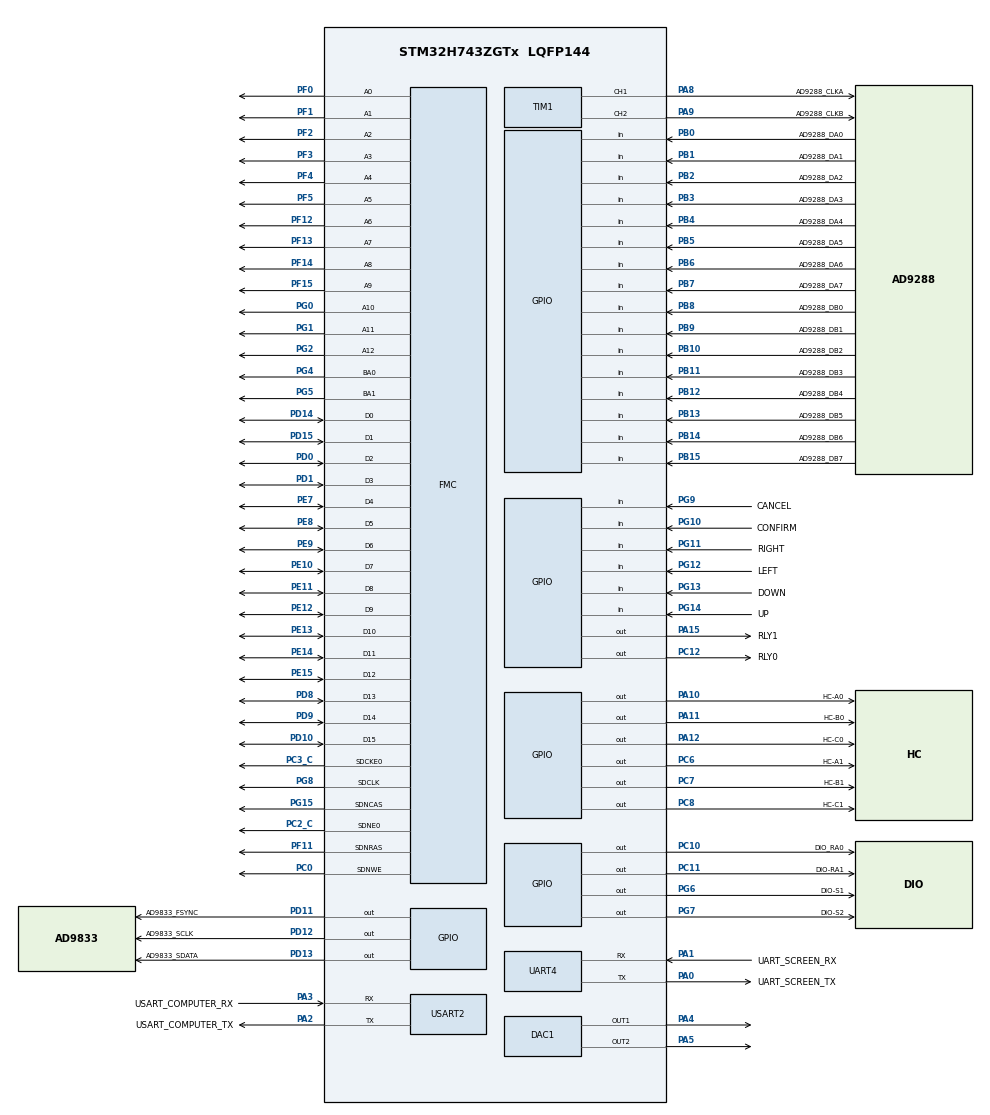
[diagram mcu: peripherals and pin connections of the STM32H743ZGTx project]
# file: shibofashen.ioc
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DAC1.DAC_Channel-DAC_OUT1=DAC_CHANNEL_1
DAC1.DAC_Channel-DAC_OUT2=DAC_CHANNEL_2
Dma.Request0=TIM1_CH1
Dma.Request1=TIM2_CH1
Dma.Request2=TIM2_CH2
Dma.Request3=TIM2_CH3
Dma.Request4=TIM2_CH4
Dma.Request5=UART4_TX
Dma.TIM1_CH1.0.Direction=DMA_PERIPH_TO_MEMORY
Dma.TIM1_CH1.0.EventEnable=DISABLE
Dma.TIM1_CH1.0.FIFOMode=DMA_FIFOMODE_DISABLE
Dma.TIM1_CH1.0.Instance=DMA1_Stream0
Dma.TIM1_CH1.0.MemDataAlignment=DMA_MDATAALIGN_HALFWORD
Dma.TIM1_CH1.0.MemInc=DMA_MINC_ENABLE
Dma.TIM1_CH1.0.Mode=DMA_NORMAL
Dma.TIM1_CH1.0.PeriphDataAlignment=DMA_PDATAALIGN_HALFWORD
Dma.TIM1_CH1.0.PeriphInc=DMA_PINC_DISABLE
Dma.TIM1_CH1.0.Polarity=HAL_DMAMUX_REQ_GEN_RISING
Dma.TIM1_CH1.0.Priority=DMA_PRIORITY_LOW
Dma.TIM1_CH1.0.RequestNumber=1
Dma.TIM1_CH1.0.SignalID=NONE
Dma.TIM1_CH1.0.SyncEnable=DISABLE
Dma.TIM1_CH1.0.SyncPolarity=HAL_DMAMUX_SYNC_NO_EVENT
Dma.TIM1_CH1.0.SyncRequestNumber=1
Dma.TIM1_CH1.0.SyncSignalID=NONE
Dma.TIM2_CH1.1.Direction=DMA_PERIPH_TO_MEMORY
Dma.TIM2_CH1.1.EventEnable=DISABLE
Dma.TIM2_CH1.1.FIFOMode=DMA_FIFOMODE_DISABLE
Dma.TIM2_CH1.1.Instance=DMA1_Stream1
Dma.TIM2_CH1.1.MemDataAlignment=DMA_MDATAALIGN_WORD
Dma.TIM2_CH1.1.MemInc=DMA_MINC_ENABLE
Dma.TIM2_CH1.1.Mode=DMA_NORMAL
Dma.TIM2_CH1.1.PeriphDataAlignment=DMA_PDATAALIGN_WORD
Dma.TIM2_CH1.1.PeriphInc=DMA_PINC_DISABLE
Dma.TIM2_CH1.1.Polarity=HAL_DMAMUX_REQ_GEN_RISING
Dma.TIM2_CH1.1.Priority=DMA_PRIORITY_LOW
Dma.TIM2_CH1.1.RequestNumber=1
Dma.TIM2_CH1.1.SignalID=NONE
Dma.TIM2_CH1.1.SyncEnable=DISABLE
Dma.TIM2_CH1.1.SyncPolarity=HAL_DMAMUX_SYNC_NO_EVENT
Dma.TIM2_CH1.1.SyncRequestNumber=1
Dma.TIM2_CH1.1.SyncSignalID=NONE
Dma.TIM2_CH2.2.Direction=DMA_PERIPH_TO_MEMORY
Dma.TIM2_CH2.2.EventEnable=DISABLE
Dma.TIM2_CH2.2.FIFOMode=DMA_FIFOMODE_DISABLE
Dma.TIM2_CH2.2.Instance=DMA1_Stream2
Dma.TIM2_CH2.2.MemDataAlignment=DMA_MDATAALIGN_WORD
Dma.TIM2_CH2.2.MemInc=DMA_MINC_ENABLE
Dma.TIM2_CH2.2.Mode=DMA_NORMAL
Dma.TIM2_CH2.2.PeriphDataAlignment=DMA_PDATAALIGN_WORD
Dma.TIM2_CH2.2.PeriphInc=DMA_PINC_DISABLE
Dma.TIM2_CH2.2.Polarity=HAL_DMAMUX_REQ_GEN_RISING
Dma.TIM2_CH2.2.Priority=DMA_PRIORITY_LOW
Dma.TIM2_CH2.2.RequestNumber=1
Dma.TIM2_CH2.2.SignalID=NONE
Dma.TIM2_CH2.2.SyncEnable=DISABLE
Dma.TIM2_CH2.2.SyncPolarity=HAL_DMAMUX_SYNC_NO_EVENT
Dma.TIM2_CH2.2.SyncRequestNumber=1
Dma.TIM2_CH2.2.SyncSignalID=NONE
Dma.TIM2_CH3.3.Direction=DMA_PERIPH_TO_MEMORY
Dma.TIM2_CH3.3.EventEnable=DISABLE
Dma.TIM2_CH3.3.FIFOMode=DMA_FIFOMODE_DISABLE
Dma.TIM2_CH3.3.Instance=DMA1_Stream3
Dma.TIM2_CH3.3.MemDataAlignment=DMA_MDATAALIGN_WORD
Dma.TIM2_CH3.3.MemInc=DMA_MINC_ENABLE
Dma.TIM2_CH3.3.Mode=DMA_NORMAL
Dma.TIM2_CH3.3.PeriphDataAlignment=DMA_PDATAALIGN_WORD
Dma.TIM2_CH3.3.PeriphInc=DMA_PINC_DISABLE
Dma.TIM2_CH3.3.Polarity=HAL_DMAMUX_REQ_GEN_RISING
Dma.TIM2_CH3.3.Priority=DMA_PRIORITY_LOW
Dma.TIM2_CH3.3.RequestNumber=1
Dma.TIM2_CH3.3.SignalID=NONE
Dma.TIM2_CH3.3.SyncEnable=DISABLE
Dma.TIM2_CH3.3.SyncPolarity=HAL_DMAMUX_SYNC_NO_EVENT
Dma.TIM2_CH3.3.SyncRequestNumber=1
Dma.TIM2_CH3.3.SyncSignalID=NONE
Dma.TIM2_CH4.4.Direction=DMA_PERIPH_TO_MEMORY
Dma.TIM2_CH4.4.EventEnable=DISABLE
Dma.TIM2_CH4.4.FIFOMode=DMA_FIFOMODE_ENABLE
Dma.TIM2_CH4.4.FIFOThreshold=DMA_FIFO_THRESHOLD_FULL
Dma.TIM2_CH4.4.Instance=DMA1_Stream4
Dma.TIM2_CH4.4.MemBurst=DMA_MBURST_SINGLE
Dma.TIM2_CH4.4.MemDataAlignment=DMA_MDATAALIGN_HALFWORD
Dma.TIM2_CH4.4.MemInc=DMA_MINC_ENABLE
Dma.TIM2_CH4.4.Mode=DMA_NORMAL
Dma.TIM2_CH4.4.PeriphBurst=DMA_PBURST_SINGLE
Dma.TIM2_CH4.4.PeriphDataAlignment=DMA_PDATAALIGN_HALFWORD
Dma.TIM2_CH4.4.PeriphInc=DMA_PINC_DISABLE
Dma.TIM2_CH4.4.Polarity=HAL_DMAMUX_REQ_GEN_RISING
Dma.TIM2_CH4.4.Priority=DMA_PRIORITY_LOW
Dma.TIM2_CH4.4.RequestNumber=1
Dma.TIM2_CH4.4.SignalID=NONE
Dma.TIM2_CH4.4.SyncEnable=DISABLE
Dma.TIM2_CH4.4.SyncPolarity=HAL_DMAMUX_SYNC_NO_EVENT
Dma.TIM2_CH4.4.SyncRequestNumber=1
Dma.TIM2_CH4.4.SyncSignalID=NONE
Dma.UART4_TX.5.Direction=DMA_MEMORY_TO_PERIPH
Dma.UART4_TX.5.EventEnable=DISABLE
Dma.UART4_TX.5.FIFOMode=DMA_FIFOMODE_DISABLE
Dma.UART4_TX.5.Instance=DMA1_Stream5
Dma.UART4_TX.5.MemDataAlignment=DMA_MDATAALIGN_BYTE
Dma.UART4_TX.5.MemInc=DMA_MINC_ENABLE
Dma.UART4_TX.5.Mode=DMA_NORMAL
Dma.UART4_TX.5.PeriphDataAlignment=DMA_PDATAALIGN_BYTE
Dma.UART4_TX.5.PeriphInc=DMA_PINC_DISABLE
Dma.UART4_TX.5.Polarity=HAL_DMAMUX_REQ_GEN_RISING
Dma.UART4_TX.5.Priority=DMA_PRIORITY_LOW
Dma.UART4_TX.5.RequestNumber=1
Dma.UART4_TX.5.SignalID=NONE
Dma.UART4_TX.5.SyncEnable=DISABLE
Dma.UART4_TX.5.SyncPolarity=HAL_DMAMUX_SYNC_NO_EVENT
Dma.UART4_TX.5.SyncRequestNumber=1
Dma.UART4_TX.5.SyncSignalID=NONE
FMC.ColumnBitsNumber1=FMC_SDRAM_COLUMN_BITS_NUM_9
FMC.ReadPipeDelay1=FMC_SDRAM_RPIPE_DELAY_1
FMC.ReadPipeDelay2=FMC_SDRAM_RPIPE_DELAY_1
FMC.SDClockPeriod1=FMC_SDRAM_CLOCK_PERIOD_2
FMC.SDClockPeriod2=FMC_SDRAM_CLOCK_PERIOD_2
Mcu.Family=STM32H7
Mcu.Name=STM32H743ZGTx
Mcu.Package=LQFP144
NVIC.DMA1_Stream0_IRQn=true\:0\:0\:false\:false\:true\:false\:true\:true
NVIC.DMA1_Stream1_IRQn=true\:0\:0\:false\:false\:true\:false\:true\:true
NVIC.DMA1_Stream2_IRQn=true\:0\:0\:false\:false\:true\:false\:true\:true
NVIC.DMA1_Stream3_IRQn=true\:0\:0\:false\:false\:true\:false\:true\:true
NVIC.DMA1_Stream4_IRQn=true\:0\:0\:false\:false\:true\:false\:true\:true
NVIC.DMA1_Stream5_IRQn=true\:0\:0\:false\:false\:true\:false\:true\:true
NVIC.PriorityGroup=NVIC_PRIORITYGROUP_4
NVIC.TIM2_IRQn=true\:0\:0\:false\:false\:true\:true\:true\:true
NVIC.TIM3_IRQn=true\:0\:0\:false\:false\:true\:true\:true\:true
NVIC.TIM4_IRQn=true\:0\:0\:false\:false\:true\:true\:true\:true
NVIC.TIM5_IRQn=true\:0\:0\:false\:false\:true\:true\:true\:true
PA0.GPIO_Label=UART_SCREEN_TX
PA0.Mode=Asynchronous
PA0.Signal=UART4_TX
PA1.GPIO_Label=UART_SCREEN_RX
PA1.Mode=Asynchronous
PA1.Signal=UART4_RX
PA10.GPIO_Label=HC-A0
PA10.Signal=GPIO_Output
PA11.GPIO_Label=HC-B0
PA11.Signal=GPIO_Output
PA12.GPIO_Label=HC-C0
PA12.Signal=GPIO_Output
PA13\ (JTMS/SWDIO).Mode=Serial_Wire
PA13\ (JTMS/SWDIO).Signal=DEBUG_JTMS-SWDIO
PA14\ (JTCK/SWCLK).Mode=Serial_Wire
PA14\ (JTCK/SWCLK).Signal=DEBUG_JTCK-SWCLK
PA15\ (JTDI).GPIO_Label=RLY1
PA15\ (JTDI).Signal=GPIO_Output
PA2.GPIO_Label=USART_COMPUTER_TX
PA2.Mode=Asynchronous
PA2.Signal=USART2_TX
PA3.GPIO_Label=USART_COMPUTER_RX
PA3.Mode=Asynchronous
PA3.Signal=USART2_RX
PA4.Signal=COMP_DAC11_group
PA5.Signal=COMP_DAC12_group
PA8.GPIO_Label=AD9288_CLKA
PA8.Signal=S_TIM1_CH1
PA9.GPIO_Label=AD9288_CLKB
PA9.Signal=S_TIM1_CH2
PB0.GPIO_Label=AD9288_DA0
PB0.Signal=GPIO_Input
PB1.GPIO_Label=AD9288_DA1
PB1.Signal=GPIO_Input
PB10.GPIO_Label=AD9288_DB2
PB10.Signal=GPIO_Input
PB11.GPIO_Label=AD9288_DB3
PB11.Signal=GPIO_Input
PB12.GPIO_Label=AD9288_DB4
PB12.Signal=GPIO_Input
PB13.GPIO_Label=AD9288_DB5
PB13.Signal=GPIO_Input
PB14.GPIO_Label=AD9288_DB6
PB14.Signal=GPIO_Input
PB15.GPIO_Label=AD9288_DB7
PB15.Signal=GPIO_Input
PB2.GPIO_Label=AD9288_DA2
PB2.Signal=GPIO_Input
PB3\ (JTDO/TRACESWO).GPIO_Label=AD9288_DA3
PB3\ (JTDO/TRACESWO).Signal=GPIO_Input
PB4\ (NJTRST).GPIO_Label=AD9288_DA4
PB4\ (NJTRST).Signal=GPIO_Input
PB5.GPIO_Label=AD9288_DA5
PB5.Signal=GPIO_Input
PB6.GPIO_Label=AD9288_DA6
PB6.Signal=GPIO_Input
PB7.GPIO_Label=AD9288_DA7
PB7.Signal=GPIO_Input
PB8.GPIO_Label=AD9288_DB0
PB8.Signal=GPIO_Input
PB9.GPIO_Label=AD9288_DB1
PB9.Signal=GPIO_Input
PC0.Signal=FMC_SDNWE
PC10.GPIO_Label=DIO_RA0
PC10.Signal=GPIO_Output
PC11.GPIO_Label=DIO-RA1
PC11.Signal=GPIO_Output
PC12.GPIO_Label=RLY0
PC12.Signal=GPIO_Output
PC2_C.Mode=SdramChipSelect1_1
PC2_C.Signal=FMC_SDNE0
PC3_C.Mode=SdramChipSelect1_1
PC3_C.Signal=FMC_SDCKE0
PC6.GPIO_Label=HC-A1
PC6.Signal=GPIO_Output
PC7.GPIO_Label=HC-B1
PC7.Signal=GPIO_Output
PC8.GPIO_Label=HC-C1
PC8.Signal=GPIO_Output
PD0.Signal=FMC_D2_DA2
PD1.Signal=FMC_D3_DA3
PD10.Signal=FMC_D15_DA15
PD11.GPIO_Label=AD9833_FSYNC
PD11.Signal=GPIO_Output
PD12.GPIO_Label=AD9833_SCLK
PD12.Signal=GPIO_Output
PD13.GPIO_Label=AD9833_SDATA
PD13.Signal=GPIO_Output
PD14.Signal=FMC_D0_DA0
PD15.Signal=FMC_D1_DA1
PD8.Signal=FMC_D13_DA13
PD9.Signal=FMC_D14_DA14
PE10.Signal=FMC_D7_DA7
PE11.Signal=FMC_D8_DA8
PE12.Signal=FMC_D9_DA9
PE13.Signal=FMC_D10_DA10
PE14.Signal=FMC_D11_DA11
PE15.Signal=FMC_D12_DA12
PE7.Signal=FMC_D4_DA4
PE8.Signal=FMC_D5_DA5
PE9.Signal=FMC_D6_DA6
PF0.Signal=FMC_A0
PF1.Signal=FMC_A1
PF11.Signal=FMC_SDNRAS
PF12.Signal=FMC_A6
PF13.Signal=FMC_A7
PF14.Signal=FMC_A8
PF15.Signal=FMC_A9
PF2.Signal=FMC_A2
PF3.Signal=FMC_A3
PF4.Signal=FMC_A4
PF5.Signal=FMC_A5
PG0.Signal=FMC_A10
PG1.Signal=FMC_A11
PG10.GPIO_Label=CONFIRM
PG10.Signal=GPIO_Input
PG11.GPIO_Label=RIGHT
PG11.Signal=GPIO_Input
PG12.GPIO_Label=LEFT
PG12.Signal=GPIO_Input
PG13.GPIO_Label=DOWN
PG13.Signal=GPIO_Input
PG14.GPIO_Label=UP
PG14.Signal=GPIO_Input
PG15.Signal=FMC_SDNCAS
PG2.Signal=FMC_A12
PG4.Signal=FMC_A14_BA0
PG5.Signal=FMC_A15_BA1
PG6.GPIO_Label=DIO-S1
PG6.Signal=GPIO_Output
PG7.GPIO_Label=DIO-S2
PG7.Signal=GPIO_Output
PG8.Signal=FMC_SDCLK
PG9.GPIO_Label=CANCEL
PG9.Signal=GPIO_Input
PH0-OSC_IN\ (PH0).Mode=HSE-External-Oscillator
PH0-OSC_IN\ (PH0).Signal=RCC_OSC_IN
PH1-OSC_OUT\ (PH1).Mode=HSE-External-Oscillator
PH1-OSC_OUT\ (PH1).Signal=RCC_OSC_OUT
ProjectManager.HeapSize=0x200
ProjectManager.StackSize=0x400
ProjectManager.TargetToolchain=MDK-ARM V5.32
RCC.ADCFreq_Value=129000000
RCC.APB1Freq_Value=100000000
RCC.APB2Freq_Value=100000000
RCC.APB3Freq_Value=100000000
RCC.APB4Freq_Value=100000000
RCC.CortexFreq_Value=400000000
RCC.D1PPRE=RCC_APB3_DIV2
RCC.D2PPRE1=RCC_APB1_DIV2
RCC.D2PPRE2=RCC_APB2_DIV2
RCC.D3PPRE=RCC_APB4_DIV2
RCC.DIVM1=4
RCC.DIVN1=50
RCC.HCLKFreq_Value=200000000
RCC.HPRE=RCC_HCLK_DIV2
RCC.PLL2FRACN=0
RCC.PLL3FRACN=0
RCC.PLLFRACN=0
RCC.SYSCLKFreq_VALUE=400000000
RCC.SYSCLKSource=RCC_SYSCLKSOURCE_PLLCLK
RCC.USBFreq_Value=400000000
SH.COMP_DAC11_group.0=DAC1_OUT1,DAC_OUT1
SH.COMP_DAC12_group.0=DAC1_OUT2,DAC_OUT2
SH.FMC_A0.0=FMC_A0,13b-sda1
SH.FMC_A1.0=FMC_A1,13b-sda1
SH.FMC_A10.0=FMC_A10,13b-sda1
SH.FMC_A11.0=FMC_A11,13b-sda1
SH.FMC_A12.0=FMC_A12,13b-sda1
SH.FMC_A14_BA0.0=FMC_BA0,FourSdramBanks1
SH.FMC_A15_BA1.0=FMC_BA1,FourSdramBanks1
SH.FMC_A2.0=FMC_A2,13b-sda1
SH.FMC_A3.0=FMC_A3,13b-sda1
SH.FMC_A4.0=FMC_A4,13b-sda1
SH.FMC_A5.0=FMC_A5,13b-sda1
SH.FMC_A6.0=FMC_A6,13b-sda1
SH.FMC_A7.0=FMC_A7,13b-sda1
SH.FMC_A8.0=FMC_A8,13b-sda1
SH.FMC_A9.0=FMC_A9,13b-sda1
SH.FMC_D0_DA0.0=FMC_D0,sd-16b-d1
SH.FMC_D10_DA10.0=FMC_D10,sd-16b-d1
SH.FMC_D11_DA11.0=FMC_D11,sd-16b-d1
SH.FMC_D12_DA12.0=FMC_D12,sd-16b-d1
SH.FMC_D13_DA13.0=FMC_D13,sd-16b-d1
SH.FMC_D14_DA14.0=FMC_D14,sd-16b-d1
SH.FMC_D15_DA15.0=FMC_D15,sd-16b-d1
SH.FMC_D1_DA1.0=FMC_D1,sd-16b-d1
SH.FMC_D2_DA2.0=FMC_D2,sd-16b-d1
SH.FMC_D3_DA3.0=FMC_D3,sd-16b-d1
SH.FMC_D4_DA4.0=FMC_D4,sd-16b-d1
SH.FMC_D5_DA5.0=FMC_D5,sd-16b-d1
SH.FMC_D6_DA6.0=FMC_D6,sd-16b-d1
SH.FMC_D7_DA7.0=FMC_D7,sd-16b-d1
SH.FMC_D8_DA8.0=FMC_D8,sd-16b-d1
SH.FMC_D9_DA9.0=FMC_D9,sd-16b-d1
SH.FMC_SDCLK.0=FMC_SDCLK,13b-sda1
SH.FMC_SDNCAS.0=FMC_SDNCAS,13b-sda1
SH.FMC_SDNRAS.0=FMC_SDNRAS,13b-sda1
SH.FMC_SDNWE.0=FMC_SDNWE,13b-sda1
SH.S_TIM1_CH1.0=TIM1_CH1,PWM Generation1 CH1
SH.S_TIM1_CH2.0=TIM1_CH2,PWM Generation2 CH2
TIM1.Channel-PWM\ Generation1\ CH1=TIM_CHANNEL_1
TIM1.Channel-PWM\ Generation2\ CH2=TIM_CHANNEL_2
TIM2.Channel-PWM\ Generation1\ No\ Output=TIM_CHANNEL_1
TIM2.Channel-PWM\ Generation2\ No\ Output=TIM_CHANNEL_2
TIM2.Channel-PWM\ Generation3\ No\ Output=TIM_CHANNEL_3
TIM2.Channel-PWM\ Generation4\ No\ Output=TIM_CHANNEL_4
TIM2.Period=8-1
TIM2.Prescaler=1-1
TIM2.Pulse-PWM\ Generation1\ No\ Output=1
TIM2.Pulse-PWM\ Generation2\ No\ Output=3
TIM2.Pulse-PWM\ Generation3\ No\ Output=5
TIM2.Pulse-PWM\ Generation4\ No\ Output=7
TIM3.Period=2000-1
TIM3.Prescaler=20000-1
TIM5.Period=10000-1
TIM5.Prescaler=200-1
USART2.VirtualMode-Asynchronous=VM_ASYNC
VP_TIM1_VS_ClockSourceINT.Mode=Internal
VP_TIM2_VS_ClockSourceINT.Mode=Internal
VP_TIM2_VS_no_output1.Mode=PWM Generation1 No Output
VP_TIM2_VS_no_output2.Mode=PWM Generation2 No Output
VP_TIM2_VS_no_output3.Mode=PWM Generation3 No Output
VP_TIM2_VS_no_output4.Mode=PWM Generation4 No Output
VP_TIM3_VS_ClockSourceINT.Mode=Internal
VP_TIM4_VS_ClockSourceINT.Mode=Internal
VP_TIM5_VS_ClockSourceINT.Mode=Internal
board=custom

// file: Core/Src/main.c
/* USER CODE BEGIN Header */
/**
  ******************************************************************************
  * @file           : main.c
  * @brief          : Main program body
  ******************************************************************************
  * @attention
  *
  * Copyright (c) 2026 STMicroelectronics.
  * All rights reserved.
  *
  * This software is licensed under terms that can be found in the LICENSE file
  * in the root directory of this software component.
  * If no LICENSE file comes with this software, it is provided AS-IS.
  *
  ******************************************************************************
  */
/* USER CODE END Header */
#include "main.h"
#include "dac.h"
#include "dma.h"
#include "tim.h"
#include "usart.h"
#include "gpio.h"
#include "fmc.h"

/* USER CODE BEGIN Includes */
#include "osc.h"
#include "ad9833.h"
/* USER CODE END Includes */

void SystemClock_Config(void);

int main(void)
{

  /* MCU Configuration--------------------------------------------------------*/

  /* Reset of all peripherals, Initializes the Flash interface and the Systick. */
  HAL_Init();

  /* Configure the system clock */
  SystemClock_Config();

  /* Initialize all configured peripherals */
  MX_GPIO_Init();
  MX_DMA_Init();
  MX_FMC_Init();
  MX_TIM1_Init();
  MX_TIM2_Init();
  MX_TIM3_Init();
  MX_TIM4_Init();
  MX_TIM5_Init();
  MX_UART4_Init();
  MX_DAC1_Init();
  MX_USART2_UART_Init();
  /* USER CODE BEGIN 2 */
	Init_Osc();
	AD9833_Init(AD9833_PORT_0, AD9833_FSYNC_GPIO, AD9833_SCLK_GPIO, AD9833_SDATA_GPIO);
	AD9833_SetFrequencyQuick(25.0, AD9833_OUT_SINUS, AD9833_PORT_0, AD9833_FSYNC_GPIO, AD9833_SCLK_GPIO, AD9833_SDATA_GPIO);
  /* USER CODE END 2 */

  /* Infinite loop */
  while (1)
  {

  }
}

void SystemClock_Config(void)
{
  RCC_OscInitTypeDef RCC_OscInitStruct = {0};
  RCC_ClkInitTypeDef RCC_ClkInitStruct = {0};

  /** Supply configuration update enable
  */
  HAL_PWREx_ConfigSupply(PWR_LDO_SUPPLY);

  /** Configure the main internal regulator output voltage
  */
  __HAL_PWR_VOLTAGESCALING_CONFIG(PWR_REGULATOR_VOLTAGE_SCALE1);

  while(!__HAL_PWR_GET_FLAG(PWR_FLAG_VOSRDY)) {}

  /** Initializes the RCC Oscillators according to the specified parameters
  * in the RCC_OscInitTypeDef structure.
  */
  RCC_OscInitStruct.OscillatorType = RCC_OSCILLATORTYPE_HSI;
  RCC_OscInitStruct.HSIState = RCC_HSI_DIV1;
  RCC_OscInitStruct.HSICalibrationValue = RCC_HSICALIBRATION_DEFAULT;
  RCC_OscInitStruct.PLL.PLLState = RCC_PLL_ON;
  RCC_OscInitStruct.PLL.PLLSource = RCC_PLLSOURCE_HSI;
  RCC_OscInitStruct.PLL.PLLM = 4;
  RCC_OscInitStruct.PLL.PLLN = 50;
  RCC_OscInitStruct.PLL.PLLP = 2;
  RCC_OscInitStruct.PLL.PLLQ = 2;
  RCC_OscInitStruct.PLL.PLLR = 2;
  RCC_OscInitStruct.PLL.PLLRGE = RCC_PLL1VCIRANGE_3;
  RCC_OscInitStruct.PLL.PLLVCOSEL = RCC_PLL1VCOWIDE;
  RCC_OscInitStruct.PLL.PLLFRACN = 0;
  if (HAL_RCC_OscConfig(&RCC_OscInitStruct) != HAL_OK)
  {
    Error_Handler();
  }

  /** Initializes the CPU, AHB and APB buses clocks
  */
  RCC_ClkInitStruct.ClockType = RCC_CLOCKTYPE_HCLK|RCC_CLOCKTYPE_SYSCLK
                              |RCC_CLOCKTYPE_PCLK1|RCC_CLOCKTYPE_PCLK2
                              |RCC_CLOCKTYPE_D3PCLK1|RCC_CLOCKTYPE_D1PCLK1;
  RCC_ClkInitStruct.SYSCLKSource = RCC_SYSCLKSOURCE_PLLCLK;
  RCC_ClkInitStruct.SYSCLKDivider = RCC_SYSCLK_DIV1;
  RCC_ClkInitStruct.AHBCLKDivider = RCC_HCLK_DIV2;
  RCC_ClkInitStruct.APB3CLKDivider = RCC_APB3_DIV2;
  RCC_ClkInitStruct.APB1CLKDivider = RCC_APB1_DIV2;
  RCC_ClkInitStruct.APB2CLKDivider = RCC_APB2_DIV2;
  RCC_ClkInitStruct.APB4CLKDivider = RCC_APB4_DIV2;

  if (HAL_RCC_ClockConfig(&RCC_ClkInitStruct, FLASH_LATENCY_2) != HAL_OK)
  {
    Error_Handler();
  }
}

void Error_Handler(void)
{
  __disable_irq();
  while (1)
  {
  }
}
